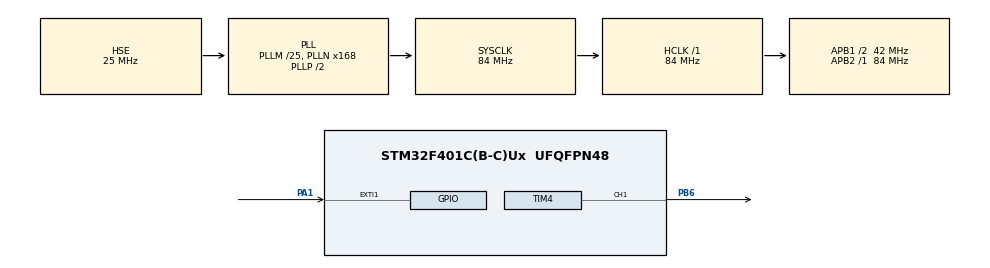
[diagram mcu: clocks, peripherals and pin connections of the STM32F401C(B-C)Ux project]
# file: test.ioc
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Mcu.Family=STM32F4
Mcu.Name=STM32F401C(B-C)Ux
Mcu.Package=UFQFPN48
NVIC.EXTI1_IRQn=true\:0\:0\:false\:false\:true\:true\:true
NVIC.PriorityGroup=NVIC_PRIORITYGROUP_4
NVIC.TIM1_UP_TIM10_IRQn=true\:0\:0\:false\:false\:true\:true\:true
PA1.GPIO_PuPd=GPIO_PULLDOWN
PA1.Signal=GPXTI1
PA13.Mode=Serial_Wire
PA13.Signal=SYS_JTMS-SWDIO
PA14.Mode=Serial_Wire
PA14.Signal=SYS_JTCK-SWCLK
PB6.GPIO_Speed=GPIO_SPEED_FREQ_VERY_HIGH
PB6.Signal=S_TIM4_CH1
PH0\ -\ OSC_IN.Mode=HSE-External-Oscillator
PH0\ -\ OSC_IN.Signal=RCC_OSC_IN
PH1\ -\ OSC_OUT.Mode=HSE-External-Oscillator
PH1\ -\ OSC_OUT.Signal=RCC_OSC_OUT
ProjectManager.HeapSize=0x2000
ProjectManager.StackSize=0x4000
ProjectManager.TargetToolchain=STM32CubeIDE
RCC.48MHZClocksFreq_Value=42000000
RCC.AHBFreq_Value=84000000
RCC.APB1CLKDivider=RCC_HCLK_DIV2
RCC.APB1Freq_Value=42000000
RCC.APB1TimFreq_Value=84000000
RCC.APB2Freq_Value=84000000
RCC.APB2TimFreq_Value=84000000
RCC.CortexFreq_Value=84000000
RCC.HCLKFreq_Value=84000000
RCC.HSE_VALUE=25000000
RCC.HSI_VALUE=16000000
RCC.LSE_VALUE=32768
RCC.PLLM=25
RCC.PLLN=168
RCC.PLLSourceVirtual=RCC_PLLSOURCE_HSE
RCC.SYSCLKFreq_VALUE=84000000
RCC.SYSCLKSource=RCC_SYSCLKSOURCE_PLLCLK
RCC.VCOOutputFreq_Value=168000000
SH.S_TIM4_CH1.0=TIM4_CH1,PWM Generation1 CH1
TIM1.Period=65535
TIM1.Prescaler=83
TIM1.TIM_MasterOutputTrigger=TIM_TRGO_RESET
TIM4.Channel-PWM\ Generation1\ CH1=TIM_CHANNEL_1
VP_TIM1_VS_ClockSourceINT.Mode=Internal
VP_TIM4_VS_ClockSourceINT.Mode=Internal
board=custom

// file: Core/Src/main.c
/* USER CODE BEGIN Header */
/**
 ******************************************************************************
 * @file           : main.c
 * @brief          : Main program body
 ******************************************************************************
 * @attention
 *
 * <h2><center>&copy; Copyright (c) 2020 STMicroelectronics.
 * All rights reserved.</center></h2>
 *
 * This software component is licensed by ST under BSD 3-Clause license,
 * the "License"; You may not use this file except in compliance with the
 * License. You may obtain a copy of the License at:
 *                        opensource.org/licenses/BSD-3-Clause
 *
 ******************************************************************************
 */
/* USER CODE END Header */
#include "main.h"
#include "tim.h"
#include "gpio.h"

/* USER CODE BEGIN Includes */
#include "config.h"
#include "string.h"
/* USER CODE END Includes */

/* USER CODE BEGIN PV */
uint8_t reset = 0;

config_t config_table[] = {
		{
				.t1 = 100,
				.t2 = 1000,
				.t3 = 100,
				.A = 100
		},
		{
				.t1 = 100,
				.t2 = 1000,
				.t3 = 100,
				.A = 20
		},
		{
				.t1 = 1200,
				.t2 = 100,
				.t3 = 5000,
				.A = 100
		}
};

config_t cfg = { 0 };
/* USER CODE END PV */

void SystemClock_Config(void);
/* USER CODE BEGIN PFP */
/**
 * @brief rises led to maximum brightness
 * @param cfg - config structure that contains certain data
 */
void rise(config_t cfg);
/**
 * @brief resets to low level
 * @param cfg - config structure that contains certain data
 */
void fall(config_t cfg);
/* USER CODE END PFP */

/* USER CODE BEGIN 0 */
void tim1_irq(void){
	static int i = 0;
	static int state = 1;
	switch(state){
	case 1:
		if(i == (float)cfg.A/100.0 * 65535.0){
			state = 2;
			HAL_TIM_Base_Stop_IT(&htim1);
			TIM4->CCR1 = i;
		}
		else{
			TIM4->CCR1 = i++;
		}
		break;
	case 2:
		if(i == 0){
			state = 1;
			HAL_TIM_Base_Stop_IT(&htim1);
			TIM4->CCR1 = 0;
			i = 0;
		}
		else{
			TIM4->CCR1 = i--;
		}
		break;
	}
}

void delay_us(uint64_t delay){
	htim1.Instance->CNT = 0; // reset counter
	HAL_TIM_Base_Start(&htim1);
	uint16_t init = (uint16_t)__HAL_TIM_GET_COUNTER(&htim1);
	while(((uint16_t)__HAL_TIM_GET_COUNTER(&htim1)-init) < delay);
	HAL_TIM_Base_Stop(&htim1);
}

void ext_irq(void){
	reset = 1;
}
/* USER CODE END 0 */

int main(void)
{
	/* USER CODE BEGIN 1 */
	uint8_t next_cfg = 0;
	cfg = config_read();
	uint8_t error = 1;
	for(int i = 0; i < 3; i++){
		if (memcmp(&cfg, &config_table[i], sizeof(config_t)) == 0) {
			next_cfg = i + 1;
			if (next_cfg >= 3)
				next_cfg = 0;
			error = 0;
		}
	}
	if (error){
		memcpy(&cfg, &config_table[0], sizeof(config_t));
		config_save(&cfg);
	}
	/* USER CODE END 1 */

	/* MCU Configuration--------------------------------------------------------*/

	/* Reset of all peripherals, Initializes the Flash interface and the Systick. */
	HAL_Init();

	/* Configure the system clock */
	SystemClock_Config();

	/* Initialize all configured peripherals */
	MX_GPIO_Init();
	MX_TIM4_Init();
	MX_TIM1_Init();
	/* USER CODE BEGIN 2 */
	int i = 0;
	HAL_TIM_PWM_Start(&htim4, TIM_CHANNEL_1);
	/* USER CODE END 2 */

	/* Infinite loop */
	/* USER CODE BEGIN WHILE */
	int state = 1;//rising state
	while (!reset)
	{
		switch(state){
		// rising state
		case 1:
			rise(cfg);
			state++;
			break;
			// halt state
		case 2:
			HAL_Delay(cfg.t2);
			state++;
			break;
			// falling state
		case 3:
			fall(cfg);
			state++;
			break;
		default:
			HAL_Delay(1000);
			state = 1;
			break;
		}
		/* USER CODE END WHILE */

		/* USER CODE BEGIN 3 */
	}
	// save next configuration
	config_save(&config_table[next_cfg]);
	NVIC_SystemReset();
	/* USER CODE END 3 */
}

void SystemClock_Config(void)
{
	RCC_OscInitTypeDef RCC_OscInitStruct = {0};
	RCC_ClkInitTypeDef RCC_ClkInitStruct = {0};

	/** Configure the main internal regulator output voltage
	 */
	__HAL_RCC_PWR_CLK_ENABLE();
	__HAL_PWR_VOLTAGESCALING_CONFIG(PWR_REGULATOR_VOLTAGE_SCALE2);
	/** Initializes the RCC Oscillators according to the specified parameters
	 * in the RCC_OscInitTypeDef structure.
	 */
	RCC_OscInitStruct.OscillatorType = RCC_OSCILLATORTYPE_HSE;
	RCC_OscInitStruct.HSEState = RCC_HSE_ON;
	RCC_OscInitStruct.PLL.PLLState = RCC_PLL_ON;
	RCC_OscInitStruct.PLL.PLLSource = RCC_PLLSOURCE_HSE;
	RCC_OscInitStruct.PLL.PLLM = 25;
	RCC_OscInitStruct.PLL.PLLN = 168;
	RCC_OscInitStruct.PLL.PLLP = RCC_PLLP_DIV2;
	RCC_OscInitStruct.PLL.PLLQ = 4;
	if (HAL_RCC_OscConfig(&RCC_OscInitStruct) != HAL_OK)
	{
		Error_Handler();
	}
	/** Initializes the CPU, AHB and APB buses clocks
	 */
	RCC_ClkInitStruct.ClockType = RCC_CLOCKTYPE_HCLK|RCC_CLOCKTYPE_SYSCLK
			|RCC_CLOCKTYPE_PCLK1|RCC_CLOCKTYPE_PCLK2;
	RCC_ClkInitStruct.SYSCLKSource = RCC_SYSCLKSOURCE_PLLCLK;
	RCC_ClkInitStruct.AHBCLKDivider = RCC_SYSCLK_DIV1;
	RCC_ClkInitStruct.APB1CLKDivider = RCC_HCLK_DIV2;
	RCC_ClkInitStruct.APB2CLKDivider = RCC_HCLK_DIV1;

	if (HAL_RCC_ClockConfig(&RCC_ClkInitStruct, FLASH_LATENCY_2) != HAL_OK)
	{
		Error_Handler();
	}
}

/* USER CODE BEGIN 4 */

/**
 * @code
 * 	TIM1->ARR = SYSCLK*t/max - 1;
 * @endcode
 */
void rise(config_t cfg){
	uint32_t max = (float)cfg.A/100.0 * 65535.0;
	__HAL_TIM_SET_AUTORELOAD(&htim1, 84000000.0/(float)(max) * (float)cfg.t1/1000.0 - 1);
	__HAL_TIM_SET_COUNTER(&htim1, 0);
	HAL_TIM_Base_Start_IT(&htim1);
	while(TIM4->CCR1 < max){
		if(reset)
			return;
	}
}

void fall(config_t cfg){
	uint32_t max = (float)cfg.A/100.0 * 65535.0;
	__HAL_TIM_SET_AUTORELOAD(&htim1, 84000000.0/(float)(max) * (float)cfg.t3/1000.0 - 1);
	__HAL_TIM_SET_COUNTER(&htim1, 0);
	HAL_TIM_Base_Start_IT(&htim1);
	while(TIM4->CCR1 > 0){
		if(reset)
			return;
	}
}
/* USER CODE END 4 */

void Error_Handler(void)
{
}

/************************ (C) COPYRIGHT STMicroelectronics *****END OF FILE****/
